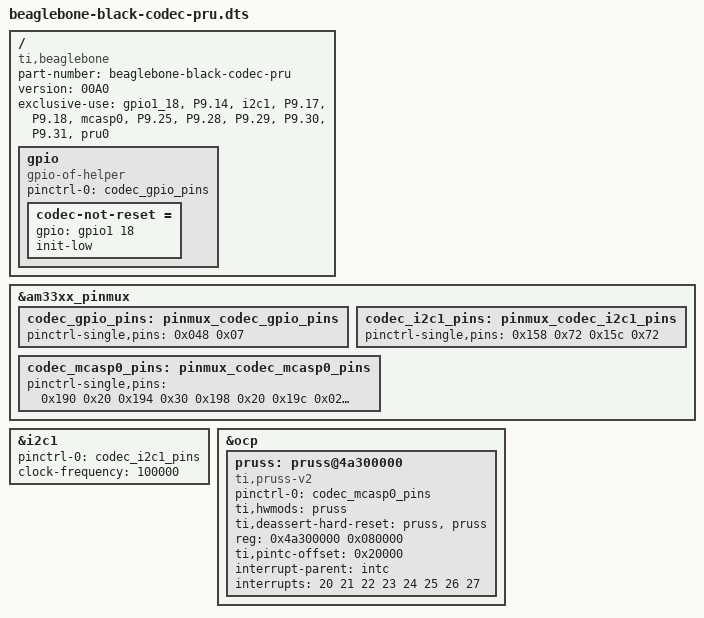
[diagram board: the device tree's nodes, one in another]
/dts-v1/;
/plugin/; /* Allow undefined label references and record them */

/ {
    compatible = "ti,beaglebone", "ti,beaglebone-black", "ti,beaglebone-green";

    /* Identification */
    part-number = "beaglebone-black-codec-pru";
    version = "00A0";

    /* State the resources this cape uses */
    exclusive-use =
        "gpio1_18",
        "P9.14", /* gpio1_18 */
        "i2c1",
        "P9.17", /* i2c1_scl */
        "P9.18", /* i2c1_sda */
        "mcasp0",
        "P9.25", /* mcasp0_ahclkx */
        "P9.28", /* mcasp0_axr2 */
        "P9.29", /* mcasp0_fsx */
        "P9.30", /* mcasp0_axr0 */
        "P9.31", /* mcasp0_aclkx */
        "pru0";

    /* Documentation: https://www.kernel.org/doc/Documentation/devicetree/bindings/pinctrl/pinctrl-single.txt */
    fragment@0 {
        target = <&am33xx_pinmux>;

        __overlay__ {
            codec_gpio_pins: pinmux_codec_gpio_pins {
                pinctrl-single,pins = <
                    0x048 0x07 /* gpio1_18: output, pull down, mode 7 */
                >;
            };

            codec_i2c1_pins: pinmux_codec_i2c1_pins {
                pinctrl-single,pins = <
                    0x158 0x72 /* i2c1_sda: slew control slow, input, pull up, mode 2 */
                    0x15c 0x72 /* i2c1_scl: slew control slow, input, pull up, mode 2 */
                >;
            };

            codec_mcasp0_pins: pinmux_codec_mcasp0_pins {
                pinctrl-single,pins = <
                    0x190 0x20 /* mcasp0_aclkx:  input,  pull down, mode 0 */
                    0x194 0x30 /* mcasp0_fsx:    input,  pull up,   mode 0 */
                    0x198 0x20 /* mcasp0_axr0:   input,  pull down, mode 0 */
                    0x19c 0x02 /* mcasp0_axr2:   output, pull down, mode 2 */
                    0x1ac 0x30 /* mcasp0_ahclkx: input,  pull up,   mode 0 */
                >;
            };
        };
    };

    /* Documentation: https://www.kernel.org/doc/Documentation/devicetree/bindings/i2c/i2c.txt */
    fragment@1 {
        target = <&i2c1>;

        __overlay__ {
            status = "okay";

            pinctrl-names = "default";
            pinctrl-0 = <&codec_i2c1_pins>;

            clock-frequency = <100000>;
        };
    };

    fragment@2 {
        target = <&ocp>;

        __overlay__ {
            pruss: pruss@4a300000 {
                compatible = "ti,pruss-v2";

                status = "okay";

                pinctrl-names = "default";
                pinctrl-0 = <&codec_mcasp0_pins>;

                ti,hwmods = "pruss";

                ti,deassert-hard-reset = "pruss", "pruss";

                reg = <0x4a300000 0x080000>;

                ti,pintc-offset = <0x20000>;

                interrupt-parent = <&intc>;

                interrupts = <20 21 22 23 24 25 26 27>;
            };
        };
    };

    fragment@3 {
        target-path = "/";

        __overlay__ {
            gpio {
                compatible = "gpio-of-helper";

                pinctrl-names = "default";
                pinctrl-0 = <&codec_gpio_pins>;

                codec-not-reset = {
                    gpio = <&gpio1 18 0>;

                    init-low;
                };
            };
        };
    };
};
